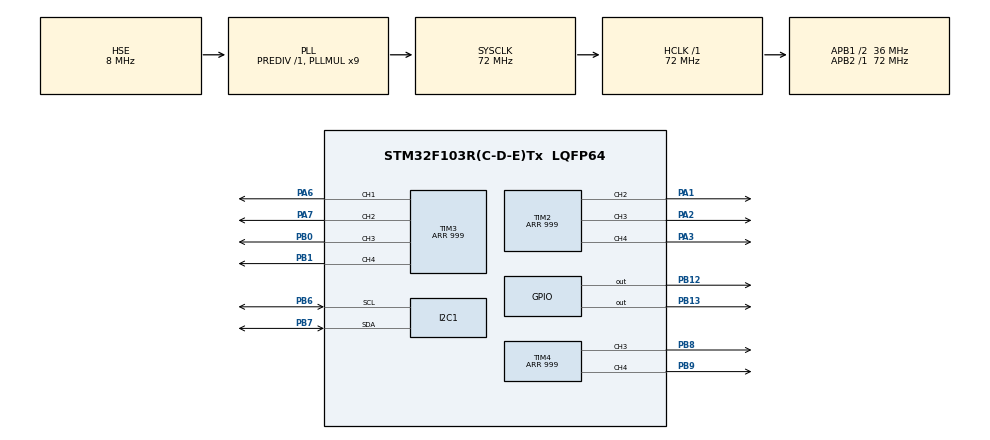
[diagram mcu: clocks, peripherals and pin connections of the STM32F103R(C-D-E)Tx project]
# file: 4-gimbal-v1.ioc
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I2C1.I2C_Mode=I2C_Fast
Mcu.Family=STM32F1
Mcu.Name=STM32F103R(C-D-E)Tx
Mcu.Package=LQFP64
NVIC.PriorityGroup=NVIC_PRIORITYGROUP_4
NVIC.TIM1_UP_IRQn=true\:0\:0\:false\:false\:true\:true\:true\:true
PA1.Signal=S_TIM2_CH2
PA13.Mode=Serial_Wire
PA13.Signal=SYS_JTMS-SWDIO
PA14.Mode=Serial_Wire
PA14.Signal=SYS_JTCK-SWCLK
PA2.Signal=S_TIM2_CH3
PA3.Signal=S_TIM2_CH4
PA6.Signal=S_TIM3_CH1
PA7.Signal=S_TIM3_CH2
PB0.Signal=S_TIM3_CH3
PB1.Signal=S_TIM3_CH4
PB12.Signal=GPIO_Output
PB13.Signal=GPIO_Output
PB6.Mode=I2C
PB6.Signal=I2C1_SCL
PB7.Mode=I2C
PB7.Signal=I2C1_SDA
PB8.Signal=S_TIM4_CH3
PB9.Signal=S_TIM4_CH4
PD0-OSC_IN.Mode=HSE-External-Oscillator
PD0-OSC_IN.Signal=RCC_OSC_IN
PD1-OSC_OUT.Mode=HSE-External-Oscillator
PD1-OSC_OUT.Signal=RCC_OSC_OUT
ProjectManager.HeapSize=0x200
ProjectManager.StackSize=0x400
ProjectManager.TargetToolchain=STM32CubeIDE
RCC.AHBFreq_Value=72000000
RCC.APB1CLKDivider=RCC_HCLK_DIV2
RCC.APB1Freq_Value=36000000
RCC.APB1TimFreq_Value=72000000
RCC.APB2Freq_Value=72000000
RCC.APB2TimFreq_Value=72000000
RCC.HCLKFreq_Value=72000000
RCC.PLLMUL=RCC_PLL_MUL9
RCC.PLLSourceVirtual=RCC_PLLSOURCE_HSE
RCC.SYSCLKFreq_VALUE=72000000
RCC.SYSCLKSource=RCC_SYSCLKSOURCE_PLLCLK
RCC.USBFreq_Value=72000000
SH.S_TIM2_CH2.0=TIM2_CH2,PWM Generation2 CH2
SH.S_TIM2_CH3.0=TIM2_CH3,PWM Generation3 CH3
SH.S_TIM2_CH4.0=TIM2_CH4,PWM Generation4 CH4
SH.S_TIM3_CH1.0=TIM3_CH1,PWM Generation1 CH1
SH.S_TIM3_CH2.0=TIM3_CH2,PWM Generation2 CH2
SH.S_TIM3_CH3.0=TIM3_CH3,PWM Generation3 CH3
SH.S_TIM3_CH4.0=TIM3_CH4,PWM Generation4 CH4
SH.S_TIM4_CH3.0=TIM4_CH3,PWM Generation3 CH3
SH.S_TIM4_CH4.0=TIM4_CH4,PWM Generation4 CH4
TIM1.Period=999
TIM1.Prescaler=71
TIM2.Channel-PWM\ Generation2\ CH2=TIM_CHANNEL_2
TIM2.Channel-PWM\ Generation3\ CH3=TIM_CHANNEL_3
TIM2.Channel-PWM\ Generation4\ CH4=TIM_CHANNEL_4
TIM2.Period=999
TIM3.Channel-PWM\ Generation1\ CH1=TIM_CHANNEL_1
TIM3.Channel-PWM\ Generation2\ CH2=TIM_CHANNEL_2
TIM3.Channel-PWM\ Generation3\ CH3=TIM_CHANNEL_3
TIM3.Channel-PWM\ Generation4\ CH4=TIM_CHANNEL_4
TIM3.Period=999
TIM4.Channel-PWM\ Generation3\ CH3=TIM_CHANNEL_3
TIM4.Channel-PWM\ Generation4\ CH4=TIM_CHANNEL_4
TIM4.Period=999
VP_TIM1_VS_ClockSourceINT.Mode=Internal
board=custom

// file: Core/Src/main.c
/* USER CODE BEGIN Header */
/**
  ******************************************************************************
  * @file           : main.c
  * @brief          : Main program body
  ******************************************************************************
  * @attention
  *
  * Copyright (c) 2026 STMicroelectronics.
  * All rights reserved.
  *
  * This software is licensed under terms that can be found in the LICENSE file
  * in the root directory of this software component.
  * If no LICENSE file comes with this software, it is provided AS-IS.
  *
  ******************************************************************************
  */
/* USER CODE END Header */
#include "main.h"

/* USER CODE BEGIN Includes */
#include "gimbal.h"
/* USER CODE END Includes */

I2C_HandleTypeDef hi2c1;

TIM_HandleTypeDef htim1;
TIM_HandleTypeDef htim2;
TIM_HandleTypeDef htim3;
TIM_HandleTypeDef htim4;

/* USER CODE BEGIN PV */
static Gimbal_State gimbal;
/* USER CODE END PV */

void SystemClock_Config(void);
static void MX_GPIO_Init(void);
static void MX_I2C1_Init(void);
static void MX_TIM3_Init(void);
static void MX_TIM2_Init(void);
static void MX_TIM4_Init(void);
static void MX_TIM1_Init(void);

int main(void)
{

  /* MCU Configuration--------------------------------------------------------*/

  /* Reset of all peripherals, Initializes the Flash interface and the Systick. */
  HAL_Init();

  /* Configure the system clock */
  SystemClock_Config();

  /* Initialize all configured peripherals */
  MX_GPIO_Init();
  MX_I2C1_Init();
  MX_TIM3_Init();
  MX_TIM2_Init();
  MX_TIM4_Init();
  MX_TIM1_Init();
  /* USER CODE BEGIN 2 */
  if (!Gimbal_Init(&gimbal, &hi2c1, &htim2, &htim3, &htim4))
  {
    /* IMU not found — blink error forever */
    while (1) { HAL_GPIO_TogglePin(GPIOB, GPIO_PIN_12); HAL_Delay(100); }
  }
  HAL_TIM_Base_Start_IT(&htim1);   /* start 1 kHz control-loop interrupt */
  HAL_GPIO_WritePin(GPIOB, GPIO_PIN_13, GPIO_PIN_SET);  /* power-on LED */
  /* USER CODE END 2 */

  /* Infinite loop */
  while (1)
  {

  }
}

void SystemClock_Config(void)
{
  RCC_OscInitTypeDef RCC_OscInitStruct = {0};
  RCC_ClkInitTypeDef RCC_ClkInitStruct = {0};

  /** Initializes the RCC Oscillators according to the specified parameters
  * in the RCC_OscInitTypeDef structure.
  */
  RCC_OscInitStruct.OscillatorType = RCC_OSCILLATORTYPE_HSE;
  RCC_OscInitStruct.HSEState = RCC_HSE_ON;
  RCC_OscInitStruct.HSEPredivValue = RCC_HSE_PREDIV_DIV1;
  RCC_OscInitStruct.HSIState = RCC_HSI_ON;
  RCC_OscInitStruct.PLL.PLLState = RCC_PLL_ON;
  RCC_OscInitStruct.PLL.PLLSource = RCC_PLLSOURCE_HSE;
  RCC_OscInitStruct.PLL.PLLMUL = RCC_PLL_MUL9;
  if (HAL_RCC_OscConfig(&RCC_OscInitStruct) != HAL_OK)
  {
    Error_Handler();
  }

  /** Initializes the CPU, AHB and APB buses clocks
  */
  RCC_ClkInitStruct.ClockType = RCC_CLOCKTYPE_HCLK|RCC_CLOCKTYPE_SYSCLK
                              |RCC_CLOCKTYPE_PCLK1|RCC_CLOCKTYPE_PCLK2;
  RCC_ClkInitStruct.SYSCLKSource = RCC_SYSCLKSOURCE_PLLCLK;
  RCC_ClkInitStruct.AHBCLKDivider = RCC_SYSCLK_DIV1;
  RCC_ClkInitStruct.APB1CLKDivider = RCC_HCLK_DIV2;
  RCC_ClkInitStruct.APB2CLKDivider = RCC_HCLK_DIV1;

  if (HAL_RCC_ClockConfig(&RCC_ClkInitStruct, FLASH_LATENCY_2) != HAL_OK)
  {
    Error_Handler();
  }
}

static void MX_I2C1_Init(void)
{

  hi2c1.Instance = I2C1;
  hi2c1.Init.ClockSpeed = 400000;
  hi2c1.Init.DutyCycle = I2C_DUTYCYCLE_2;
  hi2c1.Init.OwnAddress1 = 0;
  hi2c1.Init.AddressingMode = I2C_ADDRESSINGMODE_7BIT;
  hi2c1.Init.DualAddressMode = I2C_DUALADDRESS_DISABLE;
  hi2c1.Init.OwnAddress2 = 0;
  hi2c1.Init.GeneralCallMode = I2C_GENERALCALL_DISABLE;
  hi2c1.Init.NoStretchMode = I2C_NOSTRETCH_DISABLE;
  if (HAL_I2C_Init(&hi2c1) != HAL_OK)
  {
    Error_Handler();
  }

}

static void MX_TIM1_Init(void)
{

  TIM_ClockConfigTypeDef sClockSourceConfig = {0};
  TIM_MasterConfigTypeDef sMasterConfig = {0};

  htim1.Instance = TIM1;
  htim1.Init.Prescaler = 71;
  htim1.Init.CounterMode = TIM_COUNTERMODE_UP;
  htim1.Init.Period = 999;
  htim1.Init.ClockDivision = TIM_CLOCKDIVISION_DIV1;
  htim1.Init.RepetitionCounter = 0;
  htim1.Init.AutoReloadPreload = TIM_AUTORELOAD_PRELOAD_DISABLE;
  if (HAL_TIM_Base_Init(&htim1) != HAL_OK)
  {
    Error_Handler();
  }
  sClockSourceConfig.ClockSource = TIM_CLOCKSOURCE_INTERNAL;
  if (HAL_TIM_ConfigClockSource(&htim1, &sClockSourceConfig) != HAL_OK)
  {
    Error_Handler();
  }
  sMasterConfig.MasterOutputTrigger = TIM_TRGO_RESET;
  sMasterConfig.MasterSlaveMode = TIM_MASTERSLAVEMODE_DISABLE;
  if (HAL_TIMEx_MasterConfigSynchronization(&htim1, &sMasterConfig) != HAL_OK)
  {
    Error_Handler();
  }

}

static void MX_TIM2_Init(void)
{

  TIM_MasterConfigTypeDef sMasterConfig = {0};
  TIM_OC_InitTypeDef sConfigOC = {0};

  htim2.Instance = TIM2;
  htim2.Init.Prescaler = 0;
  htim2.Init.CounterMode = TIM_COUNTERMODE_UP;
  htim2.Init.Period = 999;
  htim2.Init.ClockDivision = TIM_CLOCKDIVISION_DIV1;
  htim2.Init.AutoReloadPreload = TIM_AUTORELOAD_PRELOAD_DISABLE;
  if (HAL_TIM_PWM_Init(&htim2) != HAL_OK)
  {
    Error_Handler();
  }
  sMasterConfig.MasterOutputTrigger = TIM_TRGO_RESET;
  sMasterConfig.MasterSlaveMode = TIM_MASTERSLAVEMODE_DISABLE;
  if (HAL_TIMEx_MasterConfigSynchronization(&htim2, &sMasterConfig) != HAL_OK)
  {
    Error_Handler();
  }
  sConfigOC.OCMode = TIM_OCMODE_PWM1;
  sConfigOC.Pulse = 0;
  sConfigOC.OCPolarity = TIM_OCPOLARITY_HIGH;
  sConfigOC.OCFastMode = TIM_OCFAST_DISABLE;
  if (HAL_TIM_PWM_ConfigChannel(&htim2, &sConfigOC, TIM_CHANNEL_2) != HAL_OK)
  {
    Error_Handler();
  }
  if (HAL_TIM_PWM_ConfigChannel(&htim2, &sConfigOC, TIM_CHANNEL_3) != HAL_OK)
  {
    Error_Handler();
  }
  if (HAL_TIM_PWM_ConfigChannel(&htim2, &sConfigOC, TIM_CHANNEL_4) != HAL_OK)
  {
    Error_Handler();
  }
  HAL_TIM_MspPostInit(&htim2);

}

static void MX_TIM3_Init(void)
{

  TIM_MasterConfigTypeDef sMasterConfig = {0};
  TIM_OC_InitTypeDef sConfigOC = {0};

  htim3.Instance = TIM3;
  htim3.Init.Prescaler = 0;
  htim3.Init.CounterMode = TIM_COUNTERMODE_UP;
  htim3.Init.Period = 999;
  htim3.Init.ClockDivision = TIM_CLOCKDIVISION_DIV1;
  htim3.Init.AutoReloadPreload = TIM_AUTORELOAD_PRELOAD_DISABLE;
  if (HAL_TIM_PWM_Init(&htim3) != HAL_OK)
  {
    Error_Handler();
  }
  sMasterConfig.MasterOutputTrigger = TIM_TRGO_RESET;
  sMasterConfig.MasterSlaveMode = TIM_MASTERSLAVEMODE_DISABLE;
  if (HAL_TIMEx_MasterConfigSynchronization(&htim3, &sMasterConfig) != HAL_OK)
  {
    Error_Handler();
  }
  sConfigOC.OCMode = TIM_OCMODE_PWM1;
  sConfigOC.Pulse = 0;
  sConfigOC.OCPolarity = TIM_OCPOLARITY_HIGH;
  sConfigOC.OCFastMode = TIM_OCFAST_DISABLE;
  if (HAL_TIM_PWM_ConfigChannel(&htim3, &sConfigOC, TIM_CHANNEL_1) != HAL_OK)
  {
    Error_Handler();
  }
  if (HAL_TIM_PWM_ConfigChannel(&htim3, &sConfigOC, TIM_CHANNEL_2) != HAL_OK)
  {
    Error_Handler();
  }
  if (HAL_TIM_PWM_ConfigChannel(&htim3, &sConfigOC, TIM_CHANNEL_3) != HAL_OK)
  {
    Error_Handler();
  }
  if (HAL_TIM_PWM_ConfigChannel(&htim3, &sConfigOC, TIM_CHANNEL_4) != HAL_OK)
  {
    Error_Handler();
  }
  HAL_TIM_MspPostInit(&htim3);

}

static void MX_TIM4_Init(void)
{

  TIM_MasterConfigTypeDef sMasterConfig = {0};
  TIM_OC_InitTypeDef sConfigOC = {0};

  htim4.Instance = TIM4;
  htim4.Init.Prescaler = 0;
  htim4.Init.CounterMode = TIM_COUNTERMODE_UP;
  htim4.Init.Period = 999;
  htim4.Init.ClockDivision = TIM_CLOCKDIVISION_DIV1;
  htim4.Init.AutoReloadPreload = TIM_AUTORELOAD_PRELOAD_DISABLE;
  if (HAL_TIM_PWM_Init(&htim4) != HAL_OK)
  {
    Error_Handler();
  }
  sMasterConfig.MasterOutputTrigger = TIM_TRGO_RESET;
  sMasterConfig.MasterSlaveMode = TIM_MASTERSLAVEMODE_DISABLE;
  if (HAL_TIMEx_MasterConfigSynchronization(&htim4, &sMasterConfig) != HAL_OK)
  {
    Error_Handler();
  }
  sConfigOC.OCMode = TIM_OCMODE_PWM1;
  sConfigOC.Pulse = 0;
  sConfigOC.OCPolarity = TIM_OCPOLARITY_HIGH;
  sConfigOC.OCFastMode = TIM_OCFAST_DISABLE;
  if (HAL_TIM_PWM_ConfigChannel(&htim4, &sConfigOC, TIM_CHANNEL_3) != HAL_OK)
  {
    Error_Handler();
  }
  if (HAL_TIM_PWM_ConfigChannel(&htim4, &sConfigOC, TIM_CHANNEL_4) != HAL_OK)
  {
    Error_Handler();
  }
  HAL_TIM_MspPostInit(&htim4);

}

static void MX_GPIO_Init(void)
{
  GPIO_InitTypeDef GPIO_InitStruct = {0};

  /* GPIO Ports Clock Enable */
  __HAL_RCC_GPIOD_CLK_ENABLE();
  __HAL_RCC_GPIOA_CLK_ENABLE();
  __HAL_RCC_GPIOB_CLK_ENABLE();

  /*Configure GPIO pin Output Level */
  HAL_GPIO_WritePin(GPIOB, GPIO_PIN_12|GPIO_PIN_13, GPIO_PIN_RESET);

  /*Configure GPIO pins : PB12 PB13 */
  GPIO_InitStruct.Pin = GPIO_PIN_12|GPIO_PIN_13;
  GPIO_InitStruct.Mode = GPIO_MODE_OUTPUT_PP;
  GPIO_InitStruct.Pull = GPIO_NOPULL;
  GPIO_InitStruct.Speed = GPIO_SPEED_FREQ_LOW;
  HAL_GPIO_Init(GPIOB, &GPIO_InitStruct);

}

/* USER CODE BEGIN 4 */
/**
  * @brief  TIM1 update interrupt — fires at 1 kHz (Prescaler=71, Period=999)
  *         Runs the full gimbal stabilisation loop.
  */
void HAL_TIM_PeriodElapsedCallback(TIM_HandleTypeDef *htim)
{
    if (htim->Instance == TIM1)
    {
        Gimbal_Update(&gimbal);
    }
}
/* USER CODE END 4 */

void Error_Handler(void)
{
  __disable_irq();
  while (1)
  {
  }
}
